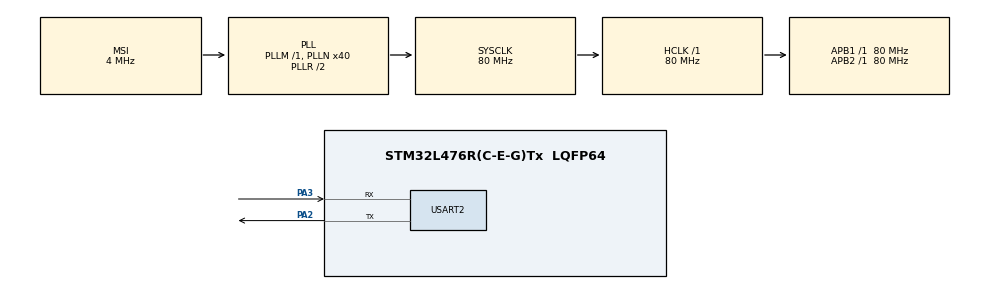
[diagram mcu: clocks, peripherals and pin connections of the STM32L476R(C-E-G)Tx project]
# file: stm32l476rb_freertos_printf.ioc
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FREERTOS.HEAP_NUMBER=4
FREERTOS.Tasks01=defaultTask,24,512,StartDefaultTask,Default,NULL,Dynamic,NULL,NULL;Debug,8,512,DebugTask,Default,NULL,Dynamic,NULL,NULL;myTask03,8,128,StartTask03,Default,NULL,Dynamic,NULL,NULL
FREERTOS.configENABLE_FPU=1
FREERTOS.configTOTAL_HEAP_SIZE=10240
FREERTOS.configUSE_STATS_FORMATTING_FUNCTIONS=1
Mcu.Family=STM32L4
Mcu.Name=STM32L476R(C-E-G)Tx
Mcu.Package=LQFP64
NVIC.PriorityGroup=NVIC_PRIORITYGROUP_4
NVIC.TIM1_UP_TIM16_IRQn=true\:0\:0\:false\:false\:true\:false\:false\:true
NVIC.TimeBase=TIM1_UP_TIM16_IRQn
NVIC.TimeBaseIP=TIM1
PA2.Mode=Asynchronous
PA2.Signal=USART2_TX
PA3.Mode=Asynchronous
PA3.Signal=USART2_RX
ProjectManager.HeapSize=0x200
ProjectManager.StackSize=0x400
ProjectManager.TargetToolchain=STM32CubeIDE
RCC.AHBFreq_Value=80000000
RCC.APB1Freq_Value=80000000
RCC.APB1TimFreq_Value=80000000
RCC.APB2Freq_Value=80000000
RCC.APB2TimFreq_Value=80000000
RCC.CortexFreq_Value=80000000
RCC.HCLKFreq_Value=80000000
RCC.HSE_VALUE=8000000
RCC.HSI_VALUE=16000000
RCC.LSE_VALUE=32768
RCC.MSI_VALUE=4000000
RCC.PLLN=40
RCC.SYSCLKFreq_VALUE=80000000
RCC.SYSCLKSource=RCC_SYSCLKSOURCE_PLLCLK
RCC.VCOOutputFreq_Value=160000000
USART2.VirtualMode-Asynchronous=VM_ASYNC
VP_FREERTOS_VS_CMSIS_V2.Mode=CMSIS_V2
VP_SYS_VS_tim1.Mode=TIM1
board=custom

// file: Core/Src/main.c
/* USER CODE BEGIN Header */
/**
  ******************************************************************************
  * @file           : main.c
  * @brief          : Main program body
  ******************************************************************************
  * @attention
  *
  * <h2><center>&copy; Copyright (c) 2020 STMicroelectronics.
  * All rights reserved.</center></h2>
  *
  * This software component is licensed by ST under Ultimate Liberty license
  * SLA0044, the "License"; You may not use this file except in compliance with
  * the License. You may obtain a copy of the License at:
  *                             www.st.com/SLA0044
  *
  ******************************************************************************
  */
/* USER CODE END Header */
#include "main.h"
#include "cmsis_os.h"
#include "usart.h"
#include "gpio.h"

/* USER CODE BEGIN Includes */
#include <stdio.h>
/* USER CODE END Includes */

/* USER CODE BEGIN PV */
extern UART_HandleTypeDef huart2;
int _write(int file, char *data, int len)
{
  HAL_StatusTypeDef status = HAL_UART_Transmit(&huart2, (uint8_t*)data, len, 1000);
  return (status == HAL_OK ? len : 0);
}
/* USER CODE END PV */

void SystemClock_Config(void);
void MX_FREERTOS_Init(void);

int main(void)
{

  /* MCU Configuration--------------------------------------------------------*/

  /* Reset of all peripherals, Initializes the Flash interface and the Systick. */
  HAL_Init();

  /* Configure the system clock */
  SystemClock_Config();

  /* Initialize all configured peripherals */
  MX_GPIO_Init();
  MX_USART2_UART_Init();
  /* USER CODE BEGIN 2 */
  printf("application start \r\n");
  /* USER CODE END 2 */

  /* Init scheduler */
  osKernelInitialize();  /* Call init function for freertos objects (in freertos.c) */
  MX_FREERTOS_Init();
  /* Start scheduler */
  osKernelStart();

  /* We should never get here as control is now taken by the scheduler */
  /* Infinite loop */
  while (1)
  {

  }
}

void SystemClock_Config(void)
{
  RCC_OscInitTypeDef RCC_OscInitStruct = {0};
  RCC_ClkInitTypeDef RCC_ClkInitStruct = {0};
  RCC_PeriphCLKInitTypeDef PeriphClkInit = {0};

  /** Initializes the RCC Oscillators according to the specified parameters
  * in the RCC_OscInitTypeDef structure.
  */
  RCC_OscInitStruct.OscillatorType = RCC_OSCILLATORTYPE_MSI;
  RCC_OscInitStruct.MSIState = RCC_MSI_ON;
  RCC_OscInitStruct.MSICalibrationValue = 0;
  RCC_OscInitStruct.MSIClockRange = RCC_MSIRANGE_6;
  RCC_OscInitStruct.PLL.PLLState = RCC_PLL_ON;
  RCC_OscInitStruct.PLL.PLLSource = RCC_PLLSOURCE_MSI;
  RCC_OscInitStruct.PLL.PLLM = 1;
  RCC_OscInitStruct.PLL.PLLN = 40;
  RCC_OscInitStruct.PLL.PLLP = RCC_PLLP_DIV7;
  RCC_OscInitStruct.PLL.PLLQ = RCC_PLLQ_DIV2;
  RCC_OscInitStruct.PLL.PLLR = RCC_PLLR_DIV2;
  if (HAL_RCC_OscConfig(&RCC_OscInitStruct) != HAL_OK)
  {
    Error_Handler();
  }
  /** Initializes the CPU, AHB and APB buses clocks
  */
  RCC_ClkInitStruct.ClockType = RCC_CLOCKTYPE_HCLK|RCC_CLOCKTYPE_SYSCLK
                              |RCC_CLOCKTYPE_PCLK1|RCC_CLOCKTYPE_PCLK2;
  RCC_ClkInitStruct.SYSCLKSource = RCC_SYSCLKSOURCE_PLLCLK;
  RCC_ClkInitStruct.AHBCLKDivider = RCC_SYSCLK_DIV1;
  RCC_ClkInitStruct.APB1CLKDivider = RCC_HCLK_DIV1;
  RCC_ClkInitStruct.APB2CLKDivider = RCC_HCLK_DIV1;

  if (HAL_RCC_ClockConfig(&RCC_ClkInitStruct, FLASH_LATENCY_4) != HAL_OK)
  {
    Error_Handler();
  }
  PeriphClkInit.PeriphClockSelection = RCC_PERIPHCLK_USART2;
  PeriphClkInit.Usart2ClockSelection = RCC_USART2CLKSOURCE_PCLK1;
  if (HAL_RCCEx_PeriphCLKConfig(&PeriphClkInit) != HAL_OK)
  {
    Error_Handler();
  }
  /** Configure the main internal regulator output voltage
  */
  if (HAL_PWREx_ControlVoltageScaling(PWR_REGULATOR_VOLTAGE_SCALE1) != HAL_OK)
  {
    Error_Handler();
  }
}

void HAL_TIM_PeriodElapsedCallback(TIM_HandleTypeDef *htim)
{
  if (htim->Instance == TIM1) {
    HAL_IncTick();
  }
}

void Error_Handler(void)
{
}

/************************ (C) COPYRIGHT STMicroelectronics *****END OF FILE****/

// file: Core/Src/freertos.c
/* USER CODE BEGIN Header */
/**
  ******************************************************************************
  * File Name          : freertos.c
  * Description        : Code for freertos applications
  ******************************************************************************
  * @attention
  *
  * <h2><center>&copy; Copyright (c) 2020 STMicroelectronics.
  * All rights reserved.</center></h2>
  *
  * This software component is licensed by ST under Ultimate Liberty license
  * SLA0044, the "License"; You may not use this file except in compliance with
  * the License. You may obtain a copy of the License at:
  *                             www.st.com/SLA0044
  *
  ******************************************************************************
  */
/* USER CODE END Header */

#include "FreeRTOS.h"
#include "task.h"
#include "main.h"
#include "cmsis_os.h"

/* USER CODE BEGIN Includes */
#include <stdio.h>
/* USER CODE END Includes */

/* Definitions for defaultTask */
osThreadId_t defaultTaskHandle;
const osThreadAttr_t defaultTask_attributes = {
  .name = "defaultTask",
  .priority = (osPriority_t) osPriorityNormal,
  .stack_size = 512 * 4
};
/* Definitions for Debug */
osThreadId_t DebugHandle;
const osThreadAttr_t Debug_attributes = {
  .name = "Debug",
  .priority = (osPriority_t) osPriorityLow,
  .stack_size = 512 * 4
};
/* Definitions for myTask03 */
osThreadId_t myTask03Handle;
const osThreadAttr_t myTask03_attributes = {
  .name = "myTask03",
  .priority = (osPriority_t) osPriorityLow,
  .stack_size = 128 * 4
};

/* USER CODE BEGIN FunctionPrototypes */
static int task_monitor(void);
/* USER CODE END FunctionPrototypes */

void StartDefaultTask(void *argument);
void DebugTask(void *argument);
void StartTask03(void *argument);

void MX_FREERTOS_Init(void); /* (MISRA C 2004 rule 8.1) */

void MX_FREERTOS_Init(void) {

  /* Create the thread(s) */
  /* creation of defaultTask */
  defaultTaskHandle = osThreadNew(StartDefaultTask, NULL, &defaultTask_attributes);

  /* creation of Debug */
  DebugHandle = osThreadNew(DebugTask, NULL, &Debug_attributes);

  /* creation of myTask03 */
  myTask03Handle = osThreadNew(StartTask03, NULL, &myTask03_attributes);

}

void StartDefaultTask(void *argument)
{
  /* USER CODE BEGIN StartDefaultTask */
  /* Infinite loop */
  float i = 0.0;
  float j = 31200.54256735;
  for(;;)
  {
    osDelay(1000);
    i += 0.001 * 1.0F;
    j += i * j;
    printf("StartDefaultTask : %3.5f, %3.5f, %3.5f, %3.5f, %3.5f, %3.5f, %3.5f, %3.5f, %3.5f, %3.5f, %3.5f, %3.5f, %3.5f, %3.5f, %3.5f, %3.5f, %3.5f, %3.5f, %3.5f, %3.5f, %3.5f, %3.5f\r\n",
        i, i, i, i, i, i, i, i, i, i, i,
        j, j, j, j, j, j, j, j, j, j, j);
  }
  /* USER CODE END StartDefaultTask */
}

void DebugTask(void *argument)
{
  /* USER CODE BEGIN DebugTask */
  /* Infinite loop */
  for(;;)
  {
    osDelay(5000);
    task_monitor();
  }
  /* USER CODE END DebugTask */
}

void StartTask03(void *argument)
{
  for(;;)
  {
    osDelay(1);
  }
}

/* USER CODE BEGIN Application */
static int task_monitor(void)
{
  char buffer[505];
  vTaskList(buffer);
  {
    printf("\r\n");
    printf("Name          State  Priority  Stack   Num\r\n");
    printf("******************************************\r\n");
    printf((char *)buffer);
    printf("******************************************\r\n");
    printf("Free Heap: %d\r\n", xPortGetMinimumEverFreeHeapSize());
  }
  return 0;
}

/* USER CODE END Application */

/************************ (C) COPYRIGHT STMicroelectronics *****END OF FILE****/
